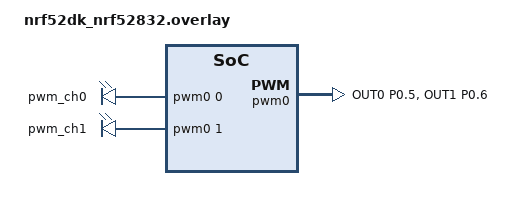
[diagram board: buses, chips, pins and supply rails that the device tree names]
/ {
    aliases {
        buzzer-pwm-a = &pwm_ch0;
        buzzer-pwm-b = &pwm_ch1;
    };

    pwmleds {
        compatible = "pwm-leds";
        pwm_ch0: pwm_ch_0 {
            pwms = <&pwm0 0 PWM_MSEC(1) PWM_POLARITY_NORMAL>;
        };
        pwm_ch1: pwm_ch_1 {
            pwms = <&pwm0 1 PWM_MSEC(1) PWM_POLARITY_INVERTED>;
        };
    };
};

&pwm0 {
    status = "okay";
    pinctrl-0 = <&pwm0_default>;
    pinctrl-1 = <&pwm0_sleep>;
    pinctrl-names = "default", "sleep";
};

&pinctrl {
    pwm0_default: pwm0_default {
        group1 {
            psels = <NRF_PSEL(PWM_OUT0, 0, 5)>,
                    <NRF_PSEL(PWM_OUT1, 0, 6)>;
        };
    };

    pwm0_sleep: pwm0_sleep {
        group1 {
            psels = <NRF_PSEL(PWM_OUT0, 0, 5)>,
                    <NRF_PSEL(PWM_OUT1, 0, 6)>;
            low-power-enable;
        };
    };
};

&uart0 {
    status = "disabled";
};
